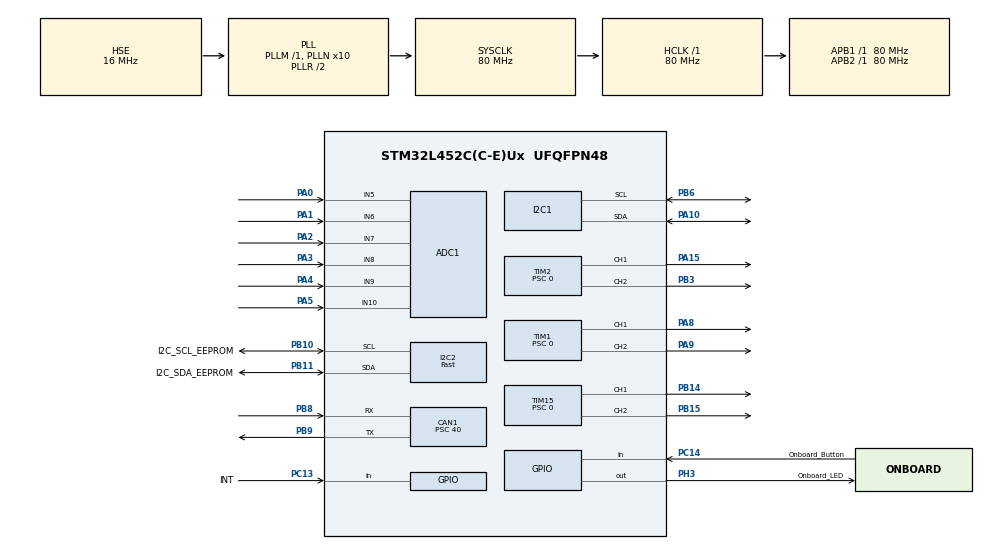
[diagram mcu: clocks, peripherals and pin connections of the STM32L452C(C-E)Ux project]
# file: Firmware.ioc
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ADC1.Channel-0\#ChannelRegularConversion=ADC_CHANNEL_5
ADC1.NbrOfConversionFlag=1
ADC1.OffsetNumber-0\#ChannelRegularConversion=ADC_OFFSET_NONE
ADC1.Rank-0\#ChannelRegularConversion=1
ADC1.SamplingTime-0\#ChannelRegularConversion=ADC_SAMPLETIME_2CYCLES_5
ADC1.master=1
CAN1.BS1=CAN_BS1_13TQ
CAN1.BS2=CAN_BS2_2TQ
CAN1.CalculateTimeQuantum=500.0
CAN1.Prescaler=40
CAN1.RFLM=DISABLE
CAN1.TXFP=ENABLE
I2C1.Timing=0x10909CEC
I2C2.Analog_Filter=I2C_ANALOGFILTER_ENABLE
I2C2.CustomTiming=Disabled
I2C2.I2C_Speed_Mode=I2C_Fast
I2C2.Timing=0x00702991
Mcu.Family=STM32L4
Mcu.Name=STM32L452C(C-E)Ux
Mcu.Package=UFQFPN48
NVIC.CAN1_RX0_IRQn=true\:0\:0\:false\:false\:true\:true\:true
NVIC.CAN1_RX1_IRQn=true\:0\:0\:false\:false\:true\:true\:true
NVIC.CAN1_SCE_IRQn=true\:0\:0\:false\:false\:true\:true\:true
NVIC.CAN1_TX_IRQn=true\:0\:0\:false\:false\:true\:true\:true
NVIC.PriorityGroup=NVIC_PRIORITYGROUP_4
PA0.Signal=ADCx_IN5
PA1.Signal=ADCx_IN6
PA10.Mode=I2C
PA10.Signal=I2C1_SDA
PA13\ (JTMS/SWDIO).Mode=Serial_Wire
PA13\ (JTMS/SWDIO).Signal=SYS_JTMS-SWDIO
PA14\ (JTCK/SWCLK).Mode=Serial_Wire
PA14\ (JTCK/SWCLK).Signal=SYS_JTCK-SWCLK
PA15\ (JTDI).Signal=S_TIM2_CH1
PA2.Signal=ADCx_IN7
PA3.Signal=ADCx_IN8
PA4.Signal=ADCx_IN9
PA5.Signal=ADCx_IN10
PA8.Signal=S_TIM1_CH1
PA9.Signal=S_TIM1_CH2
PB10.GPIO_Label=I2C_SCL_EEPROM
PB10.Mode=I2C
PB10.Signal=I2C2_SCL
PB11.GPIO_Label=I2C_SDA_EEPROM
PB11.Mode=I2C
PB11.Signal=I2C2_SDA
PB14.Signal=S_TIM15_CH1
PB15.Signal=S_TIM15_CH2
PB3\ (JTDO/TRACESWO).Signal=S_TIM2_CH2
PB6.Mode=I2C
PB6.Signal=I2C1_SCL
PB8.Mode=Master
PB8.Signal=CAN1_RX
PB9.Mode=Master
PB9.Signal=CAN1_TX
PC13.GPIO_Label=INT
PC13.GPIO_PuPd=GPIO_PULLUP
PC13.Signal=GPIO_Input
PC14-OSC32_IN\ (PC14).GPIO_Label=Onboard_Button
PC14-OSC32_IN\ (PC14).GPIO_PuPd=GPIO_PULLUP
PC14-OSC32_IN\ (PC14).Signal=GPIO_Input
PH0-OSC_IN\ (PH0).Mode=HSE-External-Oscillator
PH0-OSC_IN\ (PH0).Signal=RCC_OSC_IN
PH1-OSC_OUT\ (PH1).Mode=HSE-External-Oscillator
PH1-OSC_OUT\ (PH1).Signal=RCC_OSC_OUT
PH3-BOOT0\ (BOOT0).GPIO_Label=Onboard_LED
PH3-BOOT0\ (BOOT0).Signal=GPIO_Output
ProjectManager.HeapSize=0x200
ProjectManager.StackSize=0x400
ProjectManager.TargetToolchain=MDK-ARM V5.27
RCC.ADCFreq_Value=64000000
RCC.AHBFreq_Value=80000000
RCC.APB1Freq_Value=80000000
RCC.APB1TimFreq_Value=80000000
RCC.APB2Freq_Value=80000000
RCC.APB2TimFreq_Value=80000000
RCC.CortexFreq_Value=80000000
RCC.HCLKFreq_Value=80000000
RCC.HSE_VALUE=16000000
RCC.HSI48_VALUE=48000000
RCC.HSI_VALUE=16000000
RCC.LSE_VALUE=32768
RCC.MSI_VALUE=4000000
RCC.PLLN=10
RCC.PLLSourceVirtual=RCC_PLLSOURCE_HSE
RCC.SYSCLKFreq_VALUE=80000000
RCC.SYSCLKSource=RCC_SYSCLKSOURCE_PLLCLK
RCC.USBFreq_Value=64000000
RCC.VCOOutputFreq_Value=160000000
SH.ADCx_IN10.0=ADC1_IN10,IN10-Single-Ended
SH.ADCx_IN5.0=ADC1_IN5,IN5-Single-Ended
SH.ADCx_IN6.0=ADC1_IN6,IN6-Single-Ended
SH.ADCx_IN7.0=ADC1_IN7,IN7-Single-Ended
SH.ADCx_IN8.0=ADC1_IN8,IN8-Single-Ended
SH.ADCx_IN9.0=ADC1_IN9,IN9-Single-Ended
SH.S_TIM15_CH1.0=TIM15_CH1,PWM Generation1 CH1
SH.S_TIM15_CH2.0=TIM15_CH2,PWM Generation2 CH2
SH.S_TIM1_CH1.0=TIM1_CH1,PWM Generation1 CH1
SH.S_TIM1_CH2.0=TIM1_CH2,PWM Generation2 CH2
SH.S_TIM2_CH1.0=TIM2_CH1,PWM Generation1 CH1
SH.S_TIM2_CH2.0=TIM2_CH2,PWM Generation2 CH2
TIM1.Channel-PWM\ Generation1\ CH1=TIM_CHANNEL_1
TIM1.Channel-PWM\ Generation2\ CH2=TIM_CHANNEL_2
TIM1.Period=65535
TIM1.Prescaler=0
TIM1.TIM_MasterOutputTrigger=TIM_TRGO_OC4REF
TIM1.TIM_MasterOutputTrigger2=TIM_TRGO2_OC5REF
TIM15.Channel-PWM\ Generation1\ CH1=TIM_CHANNEL_1
TIM15.Channel-PWM\ Generation2\ CH2=TIM_CHANNEL_2
TIM15.Period=65535
TIM15.Prescaler=0
TIM2.Channel-PWM\ Generation1\ CH1=TIM_CHANNEL_1
TIM2.Channel-PWM\ Generation2\ CH2=TIM_CHANNEL_2
TIM2.Period=65535
TIM2.Prescaler=0
TIM2.TIM_MasterOutputTrigger=TIM_TRGO_OC4REF
TIM2.TIM_MasterSlaveMode=TIM_MASTERSLAVEMODE_ENABLE
VP_TIM15_VS_ClockSourceINT.Mode=Internal
VP_TIM1_VS_ClockSourceINT.Mode=Internal
VP_TIM2_VS_ClockSourceINT.Mode=Internal
board=custom

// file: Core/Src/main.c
/* USER CODE BEGIN Header */
/**
  ******************************************************************************
  * @file           : main.c
  * @brief          : Main program body
  ******************************************************************************
  * @attention
  *
  * <h2><center>&copy; Copyright (c) 2021 STMicroelectronics.
  * All rights reserved.</center></h2>
  *
  * This software component is licensed by ST under BSD 3-Clause license,
  * the "License"; You may not use this file except in compliance with the
  * License. You may obtain a copy of the License at:
  *                        opensource.org/licenses/BSD-3-Clause
  *
  ******************************************************************************
  */
/* USER CODE END Header */
#include "main.h"

/* USER CODE BEGIN Includes */
#include "FLASHMemoryMap.h"

/* USER CODE END Includes */

ADC_HandleTypeDef hadc1;

CAN_HandleTypeDef hcan1;

I2C_HandleTypeDef hi2c1;
I2C_HandleTypeDef hi2c2;

TIM_HandleTypeDef htim1;
TIM_HandleTypeDef htim2;
TIM_HandleTypeDef htim15;

void SystemClock_Config(void);
static void MX_GPIO_Init(void);
static void MX_ADC1_Init(void);
static void MX_CAN1_Init(void);
static void MX_I2C1_Init(void);
static void MX_I2C2_Init(void);
static void MX_TIM1_Init(void);
static void MX_TIM2_Init(void);
static void MX_TIM15_Init(void);

/* USER CODE BEGIN 0 */
//////////////////////////////////////////////////////////////////////////
// Связывание C и CPP кода
//////////////////////////////////////////////////////////////////////////
// Процедуры
//extern void iRidiumDevice_InitNVRAM(void);
extern void iRidiumDevice_Setup(void);
extern void iRidiumDevice_Loop(void);

/* USER CODE END 0 */

int main(void)
{
  /* USER CODE BEGIN 1 */
/*
   // Установка приоритета
   __set_PRIMASK(1);
   // Установка вектора прерывания
   SCB->VTOR = FIRMWARE_START;
   // Установка приоритета
   __set_PRIMASK(0);
   // Включение прерываний
   __enable_irq();
*/
  /* USER CODE END 1 */

  /* MCU Configuration--------------------------------------------------------*/

  /* Reset of all peripherals, Initializes the Flash interface and the Systick. */
  HAL_Init();

  /* Configure the system clock */
  SystemClock_Config();

  /* Initialize all configured peripherals */
  MX_GPIO_Init();
  MX_ADC1_Init();
  MX_CAN1_Init();
  MX_I2C1_Init();
  MX_I2C2_Init();
  MX_TIM1_Init();
  MX_TIM2_Init();
  MX_TIM15_Init();
  /* USER CODE BEGIN 2 */
  HAL_TIM_PWM_Start(&htim1, TIM_CHANNEL_1);
  HAL_TIM_PWM_Start(&htim1, TIM_CHANNEL_2);
  HAL_TIM_Base_Start(&htim1);

  HAL_TIM_PWM_Start(&htim2, TIM_CHANNEL_1);
  HAL_TIM_PWM_Start(&htim2, TIM_CHANNEL_2);
  HAL_TIM_Base_Start(&htim2);

  HAL_TIM_PWM_Start(&htim15, TIM_CHANNEL_1);
  HAL_TIM_PWM_Start(&htim15, TIM_CHANNEL_2);
  HAL_TIM_Base_Start(&htim15);

   // �?нициализация устройства
   iRidiumDevice_Setup();

  /* USER CODE END 2 */

  /* Infinite loop */
  while (1)
  {

    /* USER CODE BEGIN 3 */
   iRidiumDevice_Loop();
  }
  /* USER CODE END 3 */
}

void SystemClock_Config(void)
{
  RCC_OscInitTypeDef RCC_OscInitStruct = {0};
  RCC_ClkInitTypeDef RCC_ClkInitStruct = {0};
  RCC_PeriphCLKInitTypeDef PeriphClkInit = {0};

  /** Initializes the RCC Oscillators according to the specified parameters
  * in the RCC_OscInitTypeDef structure.
  */
  RCC_OscInitStruct.OscillatorType = RCC_OSCILLATORTYPE_HSE;
  RCC_OscInitStruct.HSEState = RCC_HSE_ON;
  RCC_OscInitStruct.PLL.PLLState = RCC_PLL_ON;
  RCC_OscInitStruct.PLL.PLLSource = RCC_PLLSOURCE_HSE;
  RCC_OscInitStruct.PLL.PLLM = 1;
  RCC_OscInitStruct.PLL.PLLN = 10;
  RCC_OscInitStruct.PLL.PLLP = RCC_PLLP_DIV7;
  RCC_OscInitStruct.PLL.PLLQ = RCC_PLLQ_DIV2;
  RCC_OscInitStruct.PLL.PLLR = RCC_PLLR_DIV2;
  if (HAL_RCC_OscConfig(&RCC_OscInitStruct) != HAL_OK)
  {
    Error_Handler();
  }
  /** Initializes the CPU, AHB and APB buses clocks
  */
  RCC_ClkInitStruct.ClockType = RCC_CLOCKTYPE_HCLK|RCC_CLOCKTYPE_SYSCLK
                              |RCC_CLOCKTYPE_PCLK1|RCC_CLOCKTYPE_PCLK2;
  RCC_ClkInitStruct.SYSCLKSource = RCC_SYSCLKSOURCE_PLLCLK;
  RCC_ClkInitStruct.AHBCLKDivider = RCC_SYSCLK_DIV1;
  RCC_ClkInitStruct.APB1CLKDivider = RCC_HCLK_DIV1;
  RCC_ClkInitStruct.APB2CLKDivider = RCC_HCLK_DIV1;

  if (HAL_RCC_ClockConfig(&RCC_ClkInitStruct, FLASH_LATENCY_4) != HAL_OK)
  {
    Error_Handler();
  }
  PeriphClkInit.PeriphClockSelection = RCC_PERIPHCLK_I2C1|RCC_PERIPHCLK_I2C2
                              |RCC_PERIPHCLK_ADC;
  PeriphClkInit.I2c1ClockSelection = RCC_I2C1CLKSOURCE_PCLK1;
  PeriphClkInit.I2c2ClockSelection = RCC_I2C2CLKSOURCE_PCLK1;
  PeriphClkInit.AdcClockSelection = RCC_ADCCLKSOURCE_PLLSAI1;
  PeriphClkInit.PLLSAI1.PLLSAI1Source = RCC_PLLSOURCE_HSE;
  PeriphClkInit.PLLSAI1.PLLSAI1M = 1;
  PeriphClkInit.PLLSAI1.PLLSAI1N = 8;
  PeriphClkInit.PLLSAI1.PLLSAI1P = RCC_PLLP_DIV7;
  PeriphClkInit.PLLSAI1.PLLSAI1Q = RCC_PLLQ_DIV2;
  PeriphClkInit.PLLSAI1.PLLSAI1R = RCC_PLLR_DIV2;
  PeriphClkInit.PLLSAI1.PLLSAI1ClockOut = RCC_PLLSAI1_ADC1CLK;
  if (HAL_RCCEx_PeriphCLKConfig(&PeriphClkInit) != HAL_OK)
  {
    Error_Handler();
  }
  /** Configure the main internal regulator output voltage
  */
  if (HAL_PWREx_ControlVoltageScaling(PWR_REGULATOR_VOLTAGE_SCALE1) != HAL_OK)
  {
    Error_Handler();
  }
}

static void MX_ADC1_Init(void)
{

  ADC_ChannelConfTypeDef sConfig = {0};

  /** Common config
  */
  hadc1.Instance = ADC1;
  hadc1.Init.ClockPrescaler = ADC_CLOCK_ASYNC_DIV1;
  hadc1.Init.Resolution = ADC_RESOLUTION_12B;
  hadc1.Init.DataAlign = ADC_DATAALIGN_RIGHT;
  hadc1.Init.ScanConvMode = ADC_SCAN_DISABLE;
  hadc1.Init.EOCSelection = ADC_EOC_SINGLE_CONV;
  hadc1.Init.LowPowerAutoWait = DISABLE;
  hadc1.Init.ContinuousConvMode = DISABLE;
  hadc1.Init.NbrOfConversion = 1;
  hadc1.Init.DiscontinuousConvMode = DISABLE;
  hadc1.Init.ExternalTrigConv = ADC_SOFTWARE_START;
  hadc1.Init.ExternalTrigConvEdge = ADC_EXTERNALTRIGCONVEDGE_NONE;
  hadc1.Init.DMAContinuousRequests = DISABLE;
  hadc1.Init.Overrun = ADC_OVR_DATA_PRESERVED;
  hadc1.Init.OversamplingMode = DISABLE;
  if (HAL_ADC_Init(&hadc1) != HAL_OK)
  {
    Error_Handler();
  }
  /** Configure Regular Channel
  */
  sConfig.Channel = ADC_CHANNEL_5;
  sConfig.Rank = ADC_REGULAR_RANK_1;
  sConfig.SamplingTime = ADC_SAMPLETIME_2CYCLES_5;
  sConfig.SingleDiff = ADC_SINGLE_ENDED;
  sConfig.OffsetNumber = ADC_OFFSET_NONE;
  sConfig.Offset = 0;
  if (HAL_ADC_ConfigChannel(&hadc1, &sConfig) != HAL_OK)
  {
    Error_Handler();
  }

}

static void MX_CAN1_Init(void)
{

  hcan1.Instance = CAN1;
  hcan1.Init.Prescaler = 40;
  hcan1.Init.Mode = CAN_MODE_NORMAL;
  hcan1.Init.SyncJumpWidth = CAN_SJW_1TQ;
  hcan1.Init.TimeSeg1 = CAN_BS1_13TQ;
  hcan1.Init.TimeSeg2 = CAN_BS2_2TQ;
  hcan1.Init.TimeTriggeredMode = DISABLE;
  hcan1.Init.AutoBusOff = ENABLE;
  hcan1.Init.AutoWakeUp = DISABLE;
  hcan1.Init.AutoRetransmission = ENABLE;
  hcan1.Init.ReceiveFifoLocked = ENABLE;
  hcan1.Init.TransmitFifoPriority = ENABLE;
  if (HAL_CAN_Init(&hcan1) != HAL_OK)
  {
    Error_Handler();
  }

}

static void MX_I2C1_Init(void)
{

  hi2c1.Instance = I2C1;
  hi2c1.Init.Timing = 0x10909CEC;
  hi2c1.Init.OwnAddress1 = 0;
  hi2c1.Init.AddressingMode = I2C_ADDRESSINGMODE_7BIT;
  hi2c1.Init.DualAddressMode = I2C_DUALADDRESS_DISABLE;
  hi2c1.Init.OwnAddress2 = 0;
  hi2c1.Init.OwnAddress2Masks = I2C_OA2_NOMASK;
  hi2c1.Init.GeneralCallMode = I2C_GENERALCALL_DISABLE;
  hi2c1.Init.NoStretchMode = I2C_NOSTRETCH_DISABLE;
  if (HAL_I2C_Init(&hi2c1) != HAL_OK)
  {
    Error_Handler();
  }
  /** Configure Analogue filter
  */
  if (HAL_I2CEx_ConfigAnalogFilter(&hi2c1, I2C_ANALOGFILTER_ENABLE) != HAL_OK)
  {
    Error_Handler();
  }
  /** Configure Digital filter
  */
  if (HAL_I2CEx_ConfigDigitalFilter(&hi2c1, 0) != HAL_OK)
  {
    Error_Handler();
  }

}

static void MX_I2C2_Init(void)
{

  hi2c2.Instance = I2C2;
  hi2c2.Init.Timing = 0x00702991;
  hi2c2.Init.OwnAddress1 = 0;
  hi2c2.Init.AddressingMode = I2C_ADDRESSINGMODE_7BIT;
  hi2c2.Init.DualAddressMode = I2C_DUALADDRESS_DISABLE;
  hi2c2.Init.OwnAddress2 = 0;
  hi2c2.Init.OwnAddress2Masks = I2C_OA2_NOMASK;
  hi2c2.Init.GeneralCallMode = I2C_GENERALCALL_DISABLE;
  hi2c2.Init.NoStretchMode = I2C_NOSTRETCH_DISABLE;
  if (HAL_I2C_Init(&hi2c2) != HAL_OK)
  {
    Error_Handler();
  }
  /** Configure Analogue filter
  */
  if (HAL_I2CEx_ConfigAnalogFilter(&hi2c2, I2C_ANALOGFILTER_ENABLE) != HAL_OK)
  {
    Error_Handler();
  }
  /** Configure Digital filter
  */
  if (HAL_I2CEx_ConfigDigitalFilter(&hi2c2, 0) != HAL_OK)
  {
    Error_Handler();
  }

}

static void MX_TIM1_Init(void)
{

  TIM_ClockConfigTypeDef sClockSourceConfig = {0};
  TIM_MasterConfigTypeDef sMasterConfig = {0};
  TIM_OC_InitTypeDef sConfigOC = {0};
  TIM_BreakDeadTimeConfigTypeDef sBreakDeadTimeConfig = {0};

  htim1.Instance = TIM1;
  htim1.Init.Prescaler = 0;
  htim1.Init.CounterMode = TIM_COUNTERMODE_UP;
  htim1.Init.Period = 65535;
  htim1.Init.ClockDivision = TIM_CLOCKDIVISION_DIV1;
  htim1.Init.RepetitionCounter = 0;
  htim1.Init.AutoReloadPreload = TIM_AUTORELOAD_PRELOAD_DISABLE;
  if (HAL_TIM_Base_Init(&htim1) != HAL_OK)
  {
    Error_Handler();
  }
  sClockSourceConfig.ClockSource = TIM_CLOCKSOURCE_INTERNAL;
  if (HAL_TIM_ConfigClockSource(&htim1, &sClockSourceConfig) != HAL_OK)
  {
    Error_Handler();
  }
  if (HAL_TIM_PWM_Init(&htim1) != HAL_OK)
  {
    Error_Handler();
  }
  sMasterConfig.MasterOutputTrigger = TIM_TRGO_OC4REF;
  sMasterConfig.MasterOutputTrigger2 = TIM_TRGO2_OC5REF;
  sMasterConfig.MasterSlaveMode = TIM_MASTERSLAVEMODE_DISABLE;
  if (HAL_TIMEx_MasterConfigSynchronization(&htim1, &sMasterConfig) != HAL_OK)
  {
    Error_Handler();
  }
  sConfigOC.OCMode = TIM_OCMODE_PWM1;
  sConfigOC.Pulse = 0;
  sConfigOC.OCPolarity = TIM_OCPOLARITY_HIGH;
  sConfigOC.OCNPolarity = TIM_OCNPOLARITY_HIGH;
  sConfigOC.OCFastMode = TIM_OCFAST_DISABLE;
  sConfigOC.OCIdleState = TIM_OCIDLESTATE_RESET;
  sConfigOC.OCNIdleState = TIM_OCNIDLESTATE_RESET;
  if (HAL_TIM_PWM_ConfigChannel(&htim1, &sConfigOC, TIM_CHANNEL_1) != HAL_OK)
  {
    Error_Handler();
  }
  if (HAL_TIM_PWM_ConfigChannel(&htim1, &sConfigOC, TIM_CHANNEL_2) != HAL_OK)
  {
    Error_Handler();
  }
  sBreakDeadTimeConfig.OffStateRunMode = TIM_OSSR_DISABLE;
  sBreakDeadTimeConfig.OffStateIDLEMode = TIM_OSSI_DISABLE;
  sBreakDeadTimeConfig.LockLevel = TIM_LOCKLEVEL_OFF;
  sBreakDeadTimeConfig.DeadTime = 0;
  sBreakDeadTimeConfig.BreakState = TIM_BREAK_DISABLE;
  sBreakDeadTimeConfig.BreakPolarity = TIM_BREAKPOLARITY_HIGH;
  sBreakDeadTimeConfig.BreakFilter = 0;
  sBreakDeadTimeConfig.Break2State = TIM_BREAK2_DISABLE;
  sBreakDeadTimeConfig.Break2Polarity = TIM_BREAK2POLARITY_HIGH;
  sBreakDeadTimeConfig.Break2Filter = 0;
  sBreakDeadTimeConfig.AutomaticOutput = TIM_AUTOMATICOUTPUT_DISABLE;
  if (HAL_TIMEx_ConfigBreakDeadTime(&htim1, &sBreakDeadTimeConfig) != HAL_OK)
  {
    Error_Handler();
  }
  HAL_TIM_MspPostInit(&htim1);

}

static void MX_TIM2_Init(void)
{

  TIM_ClockConfigTypeDef sClockSourceConfig = {0};
  TIM_MasterConfigTypeDef sMasterConfig = {0};
  TIM_OC_InitTypeDef sConfigOC = {0};

  htim2.Instance = TIM2;
  htim2.Init.Prescaler = 0;
  htim2.Init.CounterMode = TIM_COUNTERMODE_UP;
  htim2.Init.Period = 65535;
  htim2.Init.ClockDivision = TIM_CLOCKDIVISION_DIV1;
  htim2.Init.AutoReloadPreload = TIM_AUTORELOAD_PRELOAD_DISABLE;
  if (HAL_TIM_Base_Init(&htim2) != HAL_OK)
  {
    Error_Handler();
  }
  sClockSourceConfig.ClockSource = TIM_CLOCKSOURCE_INTERNAL;
  if (HAL_TIM_ConfigClockSource(&htim2, &sClockSourceConfig) != HAL_OK)
  {
    Error_Handler();
  }
  if (HAL_TIM_PWM_Init(&htim2) != HAL_OK)
  {
    Error_Handler();
  }
  sMasterConfig.MasterOutputTrigger = TIM_TRGO_OC4REF;
  sMasterConfig.MasterSlaveMode = TIM_MASTERSLAVEMODE_ENABLE;
  if (HAL_TIMEx_MasterConfigSynchronization(&htim2, &sMasterConfig) != HAL_OK)
  {
    Error_Handler();
  }
  sConfigOC.OCMode = TIM_OCMODE_PWM1;
  sConfigOC.Pulse = 0;
  sConfigOC.OCPolarity = TIM_OCPOLARITY_HIGH;
  sConfigOC.OCFastMode = TIM_OCFAST_DISABLE;
  if (HAL_TIM_PWM_ConfigChannel(&htim2, &sConfigOC, TIM_CHANNEL_1) != HAL_OK)
  {
    Error_Handler();
  }
  if (HAL_TIM_PWM_ConfigChannel(&htim2, &sConfigOC, TIM_CHANNEL_2) != HAL_OK)
  {
    Error_Handler();
  }
  HAL_TIM_MspPostInit(&htim2);

}

static void MX_TIM15_Init(void)
{

  TIM_ClockConfigTypeDef sClockSourceConfig = {0};
  TIM_MasterConfigTypeDef sMasterConfig = {0};
  TIM_OC_InitTypeDef sConfigOC = {0};
  TIM_BreakDeadTimeConfigTypeDef sBreakDeadTimeConfig = {0};

  htim15.Instance = TIM15;
  htim15.Init.Prescaler = 0;
  htim15.Init.CounterMode = TIM_COUNTERMODE_UP;
  htim15.Init.Period = 65535;
  htim15.Init.ClockDivision = TIM_CLOCKDIVISION_DIV1;
  htim15.Init.RepetitionCounter = 0;
  htim15.Init.AutoReloadPreload = TIM_AUTORELOAD_PRELOAD_DISABLE;
  if (HAL_TIM_Base_Init(&htim15) != HAL_OK)
  {
    Error_Handler();
  }
  sClockSourceConfig.ClockSource = TIM_CLOCKSOURCE_INTERNAL;
  if (HAL_TIM_ConfigClockSource(&htim15, &sClockSourceConfig) != HAL_OK)
  {
    Error_Handler();
  }
  if (HAL_TIM_PWM_Init(&htim15) != HAL_OK)
  {
    Error_Handler();
  }
  sMasterConfig.MasterOutputTrigger = TIM_TRGO_RESET;
  sMasterConfig.MasterSlaveMode = TIM_MASTERSLAVEMODE_DISABLE;
  if (HAL_TIMEx_MasterConfigSynchronization(&htim15, &sMasterConfig) != HAL_OK)
  {
    Error_Handler();
  }
  sConfigOC.OCMode = TIM_OCMODE_PWM1;
  sConfigOC.Pulse = 0;
  sConfigOC.OCPolarity = TIM_OCPOLARITY_HIGH;
  sConfigOC.OCNPolarity = TIM_OCNPOLARITY_HIGH;
  sConfigOC.OCFastMode = TIM_OCFAST_DISABLE;
  sConfigOC.OCIdleState = TIM_OCIDLESTATE_RESET;
  sConfigOC.OCNIdleState = TIM_OCNIDLESTATE_RESET;
  if (HAL_TIM_PWM_ConfigChannel(&htim15, &sConfigOC, TIM_CHANNEL_1) != HAL_OK)
  {
    Error_Handler();
  }
  if (HAL_TIM_PWM_ConfigChannel(&htim15, &sConfigOC, TIM_CHANNEL_2) != HAL_OK)
  {
    Error_Handler();
  }
  sBreakDeadTimeConfig.OffStateRunMode = TIM_OSSR_DISABLE;
  sBreakDeadTimeConfig.OffStateIDLEMode = TIM_OSSI_DISABLE;
  sBreakDeadTimeConfig.LockLevel = TIM_LOCKLEVEL_OFF;
  sBreakDeadTimeConfig.DeadTime = 0;
  sBreakDeadTimeConfig.BreakState = TIM_BREAK_DISABLE;
  sBreakDeadTimeConfig.BreakPolarity = TIM_BREAKPOLARITY_HIGH;
  sBreakDeadTimeConfig.AutomaticOutput = TIM_AUTOMATICOUTPUT_DISABLE;
  if (HAL_TIMEx_ConfigBreakDeadTime(&htim15, &sBreakDeadTimeConfig) != HAL_OK)
  {
    Error_Handler();
  }
  HAL_TIM_MspPostInit(&htim15);

}

static void MX_GPIO_Init(void)
{
  GPIO_InitTypeDef GPIO_InitStruct = {0};

  /* GPIO Ports Clock Enable */
  __HAL_RCC_GPIOC_CLK_ENABLE();
  __HAL_RCC_GPIOH_CLK_ENABLE();
  __HAL_RCC_GPIOA_CLK_ENABLE();
  __HAL_RCC_GPIOB_CLK_ENABLE();

  /*Configure GPIO pin Output Level */
  HAL_GPIO_WritePin(Onboard_LED_GPIO_Port, Onboard_LED_Pin, GPIO_PIN_RESET);

  /*Configure GPIO pins : INT_Pin Onboard_Button_Pin */
  GPIO_InitStruct.Pin = INT_Pin|Onboard_Button_Pin;
  GPIO_InitStruct.Mode = GPIO_MODE_INPUT;
  GPIO_InitStruct.Pull = GPIO_PULLUP;
  HAL_GPIO_Init(GPIOC, &GPIO_InitStruct);

  /*Configure GPIO pin : Onboard_LED_Pin */
  GPIO_InitStruct.Pin = Onboard_LED_Pin;
  GPIO_InitStruct.Mode = GPIO_MODE_OUTPUT_PP;
  GPIO_InitStruct.Pull = GPIO_NOPULL;
  GPIO_InitStruct.Speed = GPIO_SPEED_FREQ_LOW;
  HAL_GPIO_Init(Onboard_LED_GPIO_Port, &GPIO_InitStruct);

}

void Error_Handler(void)
{
}

/************************ (C) COPYRIGHT STMicroelectronics *****END OF FILE****/
